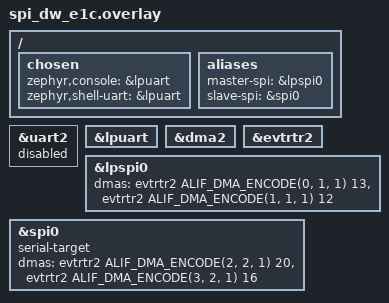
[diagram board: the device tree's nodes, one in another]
/* Copyright (C) 2026 Alif Semiconductor - All Rights Reserved.
 * Use, distribution and modification of this code is permitted under the
 * terms stated in the Alif Semiconductor Software License Agreement
 *
 * You should have received a copy of the Alif Semiconductor Software
 * License Agreement with this file. If not, please write to:
 * contact@alifsemi.com, or visit: https://alifsemi.com/license
 *
 */

/*
 * E1C HE: LPSPI0 (master) + SPI0 (slave), DMA2, evtrtr2.
 * PM: MRAM boot SOFT_OFF (HE, RTC wakeup).
 * Console: lpuart (overrides uart2 set by pm_mram_common.overlay).
 */

#include "pm_mram_he.overlay"

#include <zephyr/dt-bindings/dma/alif_dma_event_router.h>

/ {
	chosen {
		zephyr,console    = &lpuart;
		zephyr,shell-uart = &lpuart;
	};
	aliases {
		master-spi = &lpspi0;
		slave-spi = &spi0;
	};
};

&uart2 {
	status = "disabled";
};

&lpuart {
	status = "okay";
};

&dma2 {
	status = "okay";
};

&evtrtr2 {
	status = "okay";
};

&lpspi0 {
	status = "okay";
	dmas = <&evtrtr2 ALIF_DMA_ENCODE(0, 1, 1) 13>,
	       <&evtrtr2 ALIF_DMA_ENCODE(1, 1, 1) 12>;
	dma-names = "txdma", "rxdma";
};

&spi0 {
	status = "okay";
	serial-target;
	dmas = <&evtrtr2 ALIF_DMA_ENCODE(2, 2, 1) 20>,
	       <&evtrtr2 ALIF_DMA_ENCODE(3, 2, 1) 16>;
	dma-names = "txdma", "rxdma";
};
